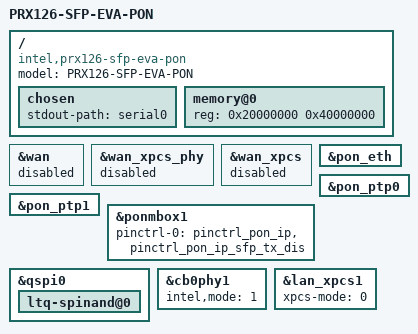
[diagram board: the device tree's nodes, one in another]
/dts-v1/;
#include "prx126-sfp-eva.dtsi"

/ {
	model = "PRX126-SFP-EVA-PON";
	compatible = "intel,prx126-sfp-eva-pon", "intel,prx126-eva", "intel,prx300";

	chosen {
		stdout-path = "serial0";
	};

	memory@0 {
		device_type = "memory";
		reg = <0x20000000 0x40000000>; /* 1024 MB */
	};
};

&wan {
	status = "disabled";
};

&wan_xpcs_phy {
	status = "disabled";
};

&wan_xpcs {
	status = "disabled";
};

&pon_eth {
	status = "okay";
};

&pon_ptp0 {
	status = "okay";
};

&pon_ptp1 {
	status = "okay";
};

&ponmbox1 {
	status = "okay";
	pinctrl-0 = <&pinctrl_pon_ip &pinctrl_pon_ip_sfp_tx_dis>;
};

&qspi0 {
	status = "okay";
	ltq-spinand@0 {
		status = "okay";
	};
};

&cb0phy1 {
	intel,mode = <1>; /*0-pcie, 1-xpcs*/
	status = "okay";
};

&lan_xpcs1 {
	status = "okay";
	xpcs-mode = <0>; /* 0 - 10G_KR_MODE, 1 - 10G_XAUI_MODE, 2 - 1G_XAUI_MODE, 3 - 2P5G_GMII_MODE */
};
